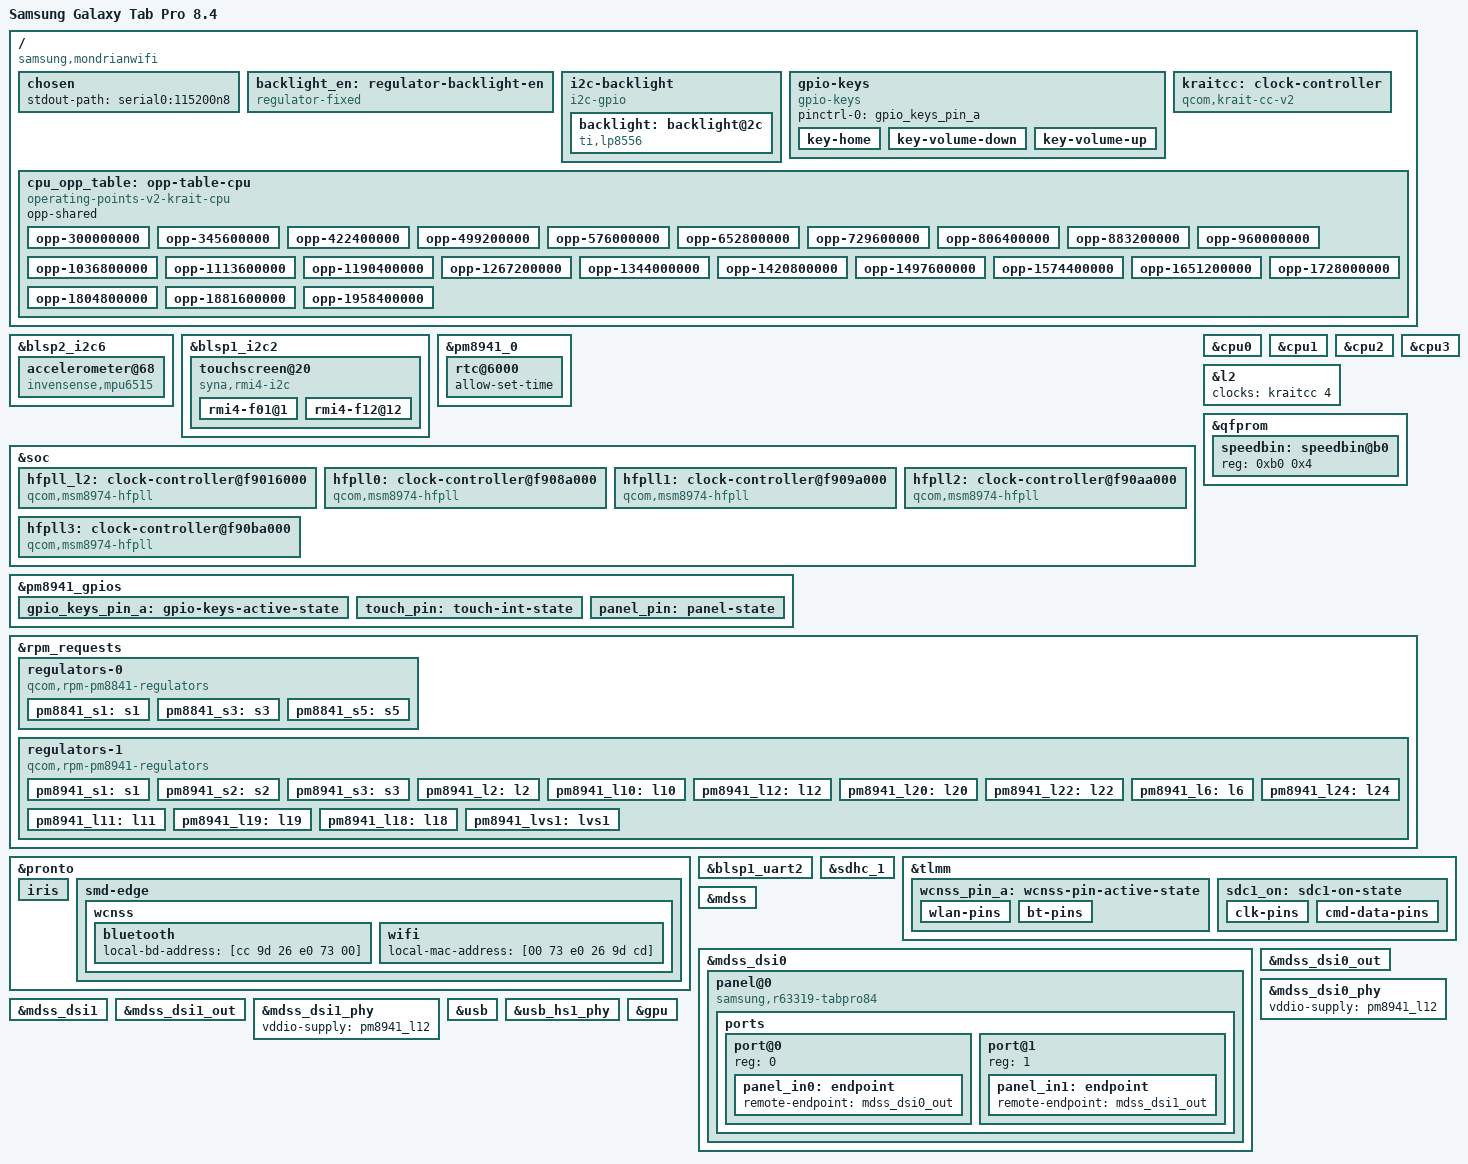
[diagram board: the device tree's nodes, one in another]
// SPDX-License-Identifier: BSD-3-Clause
/*
 * Samsung Galaxy Tab Pro 8.4 Wi-Fi (SM-T320, "mondrianwifi")
 * APQ8074 / msm8974 + PM8941 + PM8841
 *
 * DRAFT. Values traced from the downstream include chain
 * (apq8074-sec-mondrianwifi-r12.dts -> msm8974-mdss-sec.dtsi,
 *  msm8974-sec-mondrian-r12.dtsi, msm8974-sec-tabpro-common.dtsi)
 * and cross-checked against live sysfs on the running device.
 */

/dts-v1/;

#include "qcom-msm8974.dtsi"
#include "pm8841.dtsi"
#include "pm8941.dtsi"
#include <dt-bindings/input/input.h>
#include <dt-bindings/interrupt-controller/irq.h>
#include <dt-bindings/pinctrl/qcom,pmic-gpio.h>

/ {
	model = "Samsung Galaxy Tab Pro 8.4";
	compatible = "samsung,mondrianwifi", "qcom,apq8074";
	chassis-type = "tablet";

	chosen {
		stdout-path = "serial0:115200n8";
	};

	/*
	 * LP8556 backlight enable. Downstream:
	 *   lp8556,en-gpio = <&pm8941_gpios 19 0x00>
	 * The mainline lp855x binding takes a regulator, not a GPIO, so wrap it.
	 */
	backlight_en: regulator-backlight-en {
		compatible = "regulator-fixed";
		regulator-name = "backlight_en";
		gpio = <&pm8941_gpios 19 GPIO_ACTIVE_HIGH>;
		enable-active-high;
		regulator-boot-on;
	};

	/*
	 * The LP8556 sits on a BIT-BANGED i2c bus, not a hardware QUP, which is
	 * why nothing ever probed it. Downstream:
	 *   lp8556,scl-gpio = <&msmgpio 11>   lp8556,sda-gpio = <&msmgpio 10>
	 * (msmgpio == tlmm in mainline). Without this the panel scans correctly
	 * and the screen is simply unlit - indistinguishable from a dead panel.
	 */
	i2c-backlight {
		compatible = "i2c-gpio";
		sda-gpios = <&tlmm 10 (GPIO_ACTIVE_HIGH | GPIO_OPEN_DRAIN)>;
		scl-gpios = <&tlmm 11 (GPIO_ACTIVE_HIGH | GPIO_OPEN_DRAIN)>;
		i2c-gpio,delay-us = <4>;

		#address-cells = <1>;
		#size-cells = <0>;

		backlight: backlight@2c {
			compatible = "ti,lp8556";
			reg = <0x2c>;

			bl-name = "lcd-bl";
			dev-ctrl = /bits/ 8 <0x85>;
			init-brt = /bits/ 8 <0x80>;

			enable-supply = <&backlight_en>;
		};
	};

	gpio-keys {
		compatible = "gpio-keys";

		pinctrl-0 = <&gpio_keys_pin_a>;
		pinctrl-names = "default";

		key-home {
			label = "Home";
			gpios = <&pm8941_gpios 3 GPIO_ACTIVE_LOW>;
			linux,code = <KEY_HOMEPAGE>;
			debounce-interval = <15>;
		};

		key-volume-down {
			label = "Volume Down";
			gpios = <&pm8941_gpios 2 GPIO_ACTIVE_LOW>;
			linux,code = <KEY_VOLUMEDOWN>;
			debounce-interval = <15>;
		};

		key-volume-up {
			label = "Volume Up";
			gpios = <&pm8941_gpios 5 GPIO_ACTIVE_LOW>;
			linux,code = <KEY_VOLUMEUP>;
			debounce-interval = <15>;
		};
	};
};

/*
 * Touchscreen. Downstream: synaptics@20 on i2c@f9924000 (== blsp1_i2c2),
 * irq pm8941_gpios 30, avdd = l22 (3.3V live), vcc_i2c = l10 (1.85V live).
 * Wiring is identical to qcom-msm8974-samsung-hlte.dts.
 */
/*
 * Accelerometer/gyro: InvenSense MPU-6515 on BLSP2 QUP6 (vendor DT
 * msm8974-sec-mondrian-r12.dtsi: i2c@f9968000, mpu9250@68, irq gpio 86).
 * Drives screen rotation through iio-sensor-proxy.
 */
&blsp2_i2c6 {
	status = "okay";

	accelerometer@68 {
		compatible = "invensense,mpu6515";
		reg = <0x68>;
		interrupts-extended = <&tlmm 86 IRQ_TYPE_EDGE_RISING>;
		vdd-supply = <&pm8941_l18>;
		vddio-supply = <&pm8941_lvs1>;
	};
};

&blsp1_i2c2 {
	status = "okay";

	touchscreen@20 {
		compatible = "syna,rmi4-i2c";
		reg = <0x20>;

		interrupt-parent = <&pm8941_gpios>;
		interrupts = <30 IRQ_TYPE_EDGE_FALLING>;

		vdd-supply = <&pm8941_l22>;
		vio-supply = <&pm8941_l10>;

		pinctrl-0 = <&touch_pin>;
		pinctrl-names = "default";

		syna,startup-delay-ms = <100>;

		#address-cells = <1>;
		#size-cells = <0>;

		rmi4-f01@1 {
			reg = <0x1>;
			syna,nosleep-mode = <1>;
		};

		rmi4-f12@12 {
			reg = <0x12>;
			syna,sensor-type = <1>;
		};
	};
};

/* PM8941 RTC: the driver is read-only unless told otherwise; let hwclock -w
 * persist the clock, since this device has no other time source offline. */
&pm8941_0 {
	rtc@6000 {
		allow-set-time;
	};
};

/*
 * Krait CPU clocking. The bootloader parks the cores on the 300 MHz
 * secondary source and nothing in mainline ever moves them on msm8974
 * (measured: ~8x slower than rated). Wiring per the vendor kernel
 * (clock-krait-8974.c / msm8974.dtsi): five HFPLLs, the Krait clock
 * controller (v2), the speed/PVS fuse at qfprom 0xb0, and the APC supply
 * PM8841 S5 (S6..S8 are its phases). No OPP table yet: this revision only
 * registers the clocks and rails so their boot state can be read.
 */
&soc {
	hfpll_l2: clock-controller@f9016000 {
		compatible = "qcom,msm8974-hfpll", "qcom,hfpll";
		reg = <0xf9016000 0x30>, <0xf9006000 0x30>;
		#clock-cells = <0>;
		clock-output-names = "hfpll_l2";
		clocks = <&xo_board>;
		clock-names = "xo";
	};

	hfpll0: clock-controller@f908a000 {
		compatible = "qcom,msm8974-hfpll", "qcom,hfpll";
		reg = <0xf908a000 0x30>, <0xf900a000 0x30>;
		#clock-cells = <0>;
		clock-output-names = "hfpll0";
		clocks = <&xo_board>;
		clock-names = "xo";
	};

	hfpll1: clock-controller@f909a000 {
		compatible = "qcom,msm8974-hfpll", "qcom,hfpll";
		reg = <0xf909a000 0x30>, <0xf901a000 0x30>;
		#clock-cells = <0>;
		clock-output-names = "hfpll1";
		clocks = <&xo_board>;
		clock-names = "xo";
	};

	hfpll2: clock-controller@f90aa000 {
		compatible = "qcom,msm8974-hfpll", "qcom,hfpll";
		reg = <0xf90aa000 0x30>, <0xf902a000 0x30>;
		#clock-cells = <0>;
		clock-output-names = "hfpll2";
		clocks = <&xo_board>;
		clock-names = "xo";
	};

	hfpll3: clock-controller@f90ba000 {
		compatible = "qcom,msm8974-hfpll", "qcom,hfpll";
		reg = <0xf90ba000 0x30>, <0xf903a000 0x30>;
		#clock-cells = <0>;
		clock-output-names = "hfpll3";
		clocks = <&xo_board>;
		clock-names = "xo";
	};

};

/* not a memory-mapped block: the Krait muxes are reached through cp15 */
/ {
	kraitcc: clock-controller {
		compatible = "qcom,krait-cc-v2";
		clocks = <&hfpll0>, <&hfpll1>, <&hfpll2>, <&hfpll3>, <&hfpll_l2>;
		clock-names = "hfpll0", "hfpll1", "hfpll2", "hfpll3", "hfpll_l2";
		#clock-cells = <1>;
	};
};

/*
 * CPU OPPs: the vendor kernel's "qcom,speed0-pvs0-bin-v0" plan, its safe
 * fallback for this unit's speed bin 1 (no speed1 table exists downstream);
 * these voltages are what Android ran this silicon at. The ceiling is
 * raised from userspace (scaling_max_freq, /etc/local.d/cpufreq-cap.start)
 * while the RPM-voted supply is proven; see NOTES.
 */
/ {
	cpu_opp_table: opp-table-cpu {
		compatible = "operating-points-v2-krait-cpu";
		opp-shared;

		opp-300000000 {
			opp-hz = /bits/ 64 <300000000>;
			opp-microvolt = <815000 815000 1100000>;
			clock-latency-ns = <100000>;
		};

		opp-345600000 {
			opp-hz = /bits/ 64 <345600000>;
			opp-microvolt = <825000 825000 1100000>;
			clock-latency-ns = <100000>;
		};

		opp-422400000 {
			opp-hz = /bits/ 64 <422400000>;
			opp-microvolt = <835000 835000 1100000>;
			clock-latency-ns = <100000>;
		};

		opp-499200000 {
			opp-hz = /bits/ 64 <499200000>;
			opp-microvolt = <845000 845000 1100000>;
			clock-latency-ns = <100000>;
		};

		opp-576000000 {
			opp-hz = /bits/ 64 <576000000>;
			opp-microvolt = <855000 855000 1100000>;
			clock-latency-ns = <100000>;
		};

		opp-652800000 {
			opp-hz = /bits/ 64 <652800000>;
			opp-microvolt = <865000 865000 1100000>;
			clock-latency-ns = <100000>;
		};

		opp-729600000 {
			opp-hz = /bits/ 64 <729600000>;
			opp-microvolt = <875000 875000 1100000>;
			clock-latency-ns = <100000>;
		};

		opp-806400000 {
			opp-hz = /bits/ 64 <806400000>;
			opp-microvolt = <890000 890000 1100000>;
			clock-latency-ns = <100000>;
		};

		opp-883200000 {
			opp-hz = /bits/ 64 <883200000>;
			opp-microvolt = <900000 900000 1100000>;
			clock-latency-ns = <100000>;
		};

		opp-960000000 {
			opp-hz = /bits/ 64 <960000000>;
			opp-microvolt = <915000 915000 1100000>;
			clock-latency-ns = <100000>;
		};

		opp-1036800000 {
			opp-hz = /bits/ 64 <1036800000>;
			opp-microvolt = <925000 925000 1100000>;
			clock-latency-ns = <100000>;
		};

		opp-1113600000 {
			opp-hz = /bits/ 64 <1113600000>;
			opp-microvolt = <940000 940000 1100000>;
			clock-latency-ns = <100000>;
		};

		opp-1190400000 {
			opp-hz = /bits/ 64 <1190400000>;
			opp-microvolt = <950000 950000 1100000>;
			clock-latency-ns = <100000>;
		};

		opp-1267200000 {
			opp-hz = /bits/ 64 <1267200000>;
			opp-microvolt = <965000 965000 1100000>;
			clock-latency-ns = <100000>;
		};

		opp-1344000000 {
			opp-hz = /bits/ 64 <1344000000>;
			opp-microvolt = <980000 980000 1100000>;
			clock-latency-ns = <100000>;
		};

		opp-1420800000 {
			opp-hz = /bits/ 64 <1420800000>;
			opp-microvolt = <995000 995000 1100000>;
			clock-latency-ns = <100000>;
		};

		opp-1497600000 {
			opp-hz = /bits/ 64 <1497600000>;
			opp-microvolt = <1010000 1010000 1100000>;
			clock-latency-ns = <100000>;
		};

		opp-1574400000 {
			opp-hz = /bits/ 64 <1574400000>;
			opp-microvolt = <1025000 1025000 1100000>;
			clock-latency-ns = <100000>;
		};

		opp-1651200000 {
			opp-hz = /bits/ 64 <1651200000>;
			opp-microvolt = <1040000 1040000 1100000>;
			clock-latency-ns = <100000>;
		};

		opp-1728000000 {
			opp-hz = /bits/ 64 <1728000000>;
			opp-microvolt = <1055000 1055000 1100000>;
			clock-latency-ns = <100000>;
		};

		opp-1804800000 {
			opp-hz = /bits/ 64 <1804800000>;
			opp-microvolt = <1070000 1070000 1100000>;
			clock-latency-ns = <100000>;
		};

		opp-1881600000 {
			opp-hz = /bits/ 64 <1881600000>;
			opp-microvolt = <1085000 1085000 1100000>;
			clock-latency-ns = <100000>;
		};

		opp-1958400000 {
			opp-hz = /bits/ 64 <1958400000>;
			opp-microvolt = <1100000 1100000 1100000>;
			clock-latency-ns = <100000>;
		};
	};
};

&cpu0 {
	clocks = <&kraitcc 0>;
	clock-names = "cpu";
	operating-points-v2 = <&cpu_opp_table>;
	cpu-supply = <&pm8841_s5>;
	nvmem-cells = <&speedbin>;
	nvmem-cell-names = "speed_bin";
};

&cpu1 {
	clocks = <&kraitcc 1>;
	clock-names = "cpu";
	operating-points-v2 = <&cpu_opp_table>;
	cpu-supply = <&pm8841_s5>;
	nvmem-cells = <&speedbin>;
	nvmem-cell-names = "speed_bin";
};

&cpu2 {
	clocks = <&kraitcc 2>;
	clock-names = "cpu";
	operating-points-v2 = <&cpu_opp_table>;
	cpu-supply = <&pm8841_s5>;
	nvmem-cells = <&speedbin>;
	nvmem-cell-names = "speed_bin";
};

&cpu3 {
	clocks = <&kraitcc 3>;
	clock-names = "cpu";
	operating-points-v2 = <&cpu_opp_table>;
	cpu-supply = <&pm8841_s5>;
	nvmem-cells = <&speedbin>;
	nvmem-cell-names = "speed_bin";
};

&l2 {
	clocks = <&kraitcc 4>;
	clock-names = "l2";
};

&qfprom {
	/* PTE efuse: speed bin, PVS bin, PVS version (this unit: 1 / 2 / 0) */
	speedbin: speedbin@b0 {
		reg = <0xb0 0x4>;
	};
};

&pm8941_gpios {
	gpio_keys_pin_a: gpio-keys-active-state {
		pins = "gpio2", "gpio3", "gpio5";
		function = "normal";
		bias-pull-up;
		power-source = <PM8941_GPIO_S3>;
	};

	touch_pin: touch-int-state {
		pins = "gpio30";
		function = "normal";
		bias-disable;
		input-enable;
		power-source = <PM8941_GPIO_S3>;
	};

	panel_pin: panel-state {
		pins = "gpio9", "gpio14";
		function = "normal";
		bias-disable;
		power-source = <PM8941_GPIO_S3>;
		output-high;
	};
};

/*
 * Rails. Voltages below were read from live sysfs on the running device
 * (see tabpro84-port/findings/NOTES.md), not guessed:
 *   l2 = 1.200V  l10 = 1.850V  l12 = 1.800V  l22 = 3.300V
 */
&rpm_requests {
	regulators-0 {
		compatible = "qcom,rpm-pm8841-regulators";

		pm8841_s1: s1 {
			regulator-min-microvolt = <675000>;
			regulator-max-microvolt = <1050000>;
		};

		pm8841_s3: s3 {
			regulator-min-microvolt = <1050000>;
			regulator-max-microvolt = <1050000>;
		};

		/*
		 * APC (Krait) supply: 4-phase FTS S5 (+S6..S8 as phases). The
		 * SPMI arbiter denies the AP direct access to PM8841's SMPS
		 * peripherals (they read as zero), so it is voted via the RPM.
		 * Range = the vendor speed0-pvs0 plan (815 mV @ 300 MHz .. 1.1 V
		 * @ 1958 MHz); cores run in BHS mode, straight off this rail.
		 */
		pm8841_s5: s5 {
			regulator-name = "vdd_apc";
			regulator-min-microvolt = <815000>;
			regulator-max-microvolt = <1100000>;
		};
	};

	regulators-1 {
		compatible = "qcom,rpm-pm8941-regulators";

		pm8941_s1: s1 {
			regulator-min-microvolt = <1300000>;
			regulator-max-microvolt = <1300000>;
			regulator-always-on;
		};

		pm8941_s2: s2 {
			regulator-min-microvolt = <2150000>;
			regulator-max-microvolt = <2150000>;
		};

		pm8941_s3: s3 {
			regulator-min-microvolt = <1800000>;
			regulator-max-microvolt = <1800000>;
			regulator-always-on;
		};

		pm8941_l2: l2 {
			regulator-min-microvolt = <1200000>;
			regulator-max-microvolt = <1200000>;
		};

		pm8941_l10: l10 {
			regulator-min-microvolt = <1850000>;
			regulator-max-microvolt = <1850000>;
		};

		pm8941_l12: l12 {
			regulator-min-microvolt = <1800000>;
			regulator-max-microvolt = <1800000>;
			regulator-always-on;
		};

		pm8941_l20: l20 {
			regulator-min-microvolt = <2950000>;
			regulator-max-microvolt = <2950000>;
			regulator-system-load = <200000>;
			regulator-allow-set-load;
			regulator-boot-on;
		};

		pm8941_l22: l22 {
			regulator-min-microvolt = <3300000>;
			regulator-max-microvolt = <3300000>;
			regulator-boot-on;
		};

		pm8941_l6: l6 {
			regulator-min-microvolt = <1800000>;
			regulator-max-microvolt = <1800000>;
			regulator-boot-on;
		};

		pm8941_l24: l24 {
			regulator-min-microvolt = <3075000>;
			regulator-max-microvolt = <3075000>;
			regulator-boot-on;
		};

		/* WCNSS (Wi-Fi + Bluetooth) RF supplies, per every other PM8941 board */
		pm8941_l11: l11 {
			regulator-min-microvolt = <1300000>;
			regulator-max-microvolt = <1300000>;
		};

		pm8941_l19: l19 {
			regulator-min-microvolt = <2900000>;
			regulator-max-microvolt = <3350000>;
		};

		/* sensors (vendor: mpu9250-vcc / -lvs1 supplies) */
		pm8941_l18: l18 {
			regulator-min-microvolt = <2850000>;
			regulator-max-microvolt = <2850000>;
		};

		pm8941_lvs1: lvs1 {
		};
	};
};

/*
 * WCNSS: Wi-Fi and Bluetooth live on the wcn3680 behind the pronto remoteproc.
 * The signed firmware is the device's own, from the apnhlos partition
 * (image/wcnss.mdt + .b0x), installed under /lib/firmware/qcom/msm8974/mondrianwifi.
 */
&pronto {
	vddmx-supply = <&pm8841_s1>;
	vddpx-supply = <&pm8941_s3>;

	pinctrl-names = "default";
	pinctrl-0 = <&wcnss_pin_a>;

	firmware-name = "qcom/msm8974/mondrianwifi/wcnss.mdt";

	status = "okay";

	iris {
		vddxo-supply = <&pm8941_l6>;
		vddrfa-supply = <&pm8941_l11>;
		vddpa-supply = <&pm8941_l19>;
		vdddig-supply = <&pm8941_s3>;
	};

	smd-edge {
		qcom,remote-pid = <4>;
		label = "pronto";

		wcnss {
			status = "okay";

			/* addresses from the efs partition: bluetooth/bt_addr, wifi/.mac.info */
			bluetooth {
				local-bd-address = [cc 9d 26 e0 73 00];
			};

			wifi {
				local-mac-address = [00 73 e0 26 9d cd];
			};
		};
	};
};

&blsp1_uart2 {
	status = "okay";
};

&sdhc_1 {
	status = "okay";

	vmmc-supply = <&pm8941_l20>;
	vqmmc-supply = <&pm8941_s3>;

	pinctrl-0 = <&sdc1_on>;
	pinctrl-names = "default";
};

&tlmm {
	wcnss_pin_a: wcnss-pin-active-state {
		wlan-pins {
			pins = "gpio36", "gpio37", "gpio38", "gpio39", "gpio40";
			function = "wlan";
			drive-strength = <6>;
			bias-pull-down;
		};

		bt-pins {
			pins = "gpio35", "gpio43", "gpio44";
			function = "bt";
			drive-strength = <2>;
			bias-pull-down;
		};
	};

	sdc1_on: sdc1-on-state {
		clk-pins {
			pins = "sdc1_clk";
			drive-strength = <16>;
			bias-disable;
		};

		cmd-data-pins {
			pins = "sdc1_cmd", "sdc1_data";
			drive-strength = <10>;
			bias-pull-up;
		};
	};
};


&mdss {
	status = "okay";
};

&mdss_dsi0 {
	status = "okay";

	/*
	 * The panel is one physical device driven over two DSI links, each
	 * carrying one 800x2560 half. Without these the DSI manager leaves
	 * is_bonded_dsi false, each host tries to clock the FULL 1600x2560
	 * mode (~320 MHz pixel / ~1.92 GHz per lane), and the PLL rejects it:
	 *   msm_dsi_host_power_on: failed to enable link clocks. ret=-22
	 */
	qcom,dual-dsi-mode;
	qcom,master-dsi;

	vdd-supply   = <&pm8941_l22>;
	vddio-supply = <&pm8941_l12>;
	vdda-supply  = <&pm8941_l2>;

	panel@0 {
		compatible = "samsung,r63319-tabpro84";
		reg = <0>;

		/* one physical panel, one reset and one enable shared by both links */
		reset-gpios  = <&pm8941_gpios  9 GPIO_ACTIVE_LOW>;
		enable-gpios = <&pm8941_gpios 14 GPIO_ACTIVE_HIGH>;

		vdd-supply   = <&pm8941_l22>;
		vddio-supply = <&pm8941_l12>;

		backlight = <&backlight>;

		pinctrl-0 = <&panel_pin>;
		pinctrl-names = "default";

		ports {
			#address-cells = <1>;
			#size-cells = <0>;

			port@0 {
				reg = <0>;
				panel_in0: endpoint {
					remote-endpoint = <&mdss_dsi0_out>;
				};
			};

			port@1 {
				reg = <1>;
				panel_in1: endpoint {
					remote-endpoint = <&mdss_dsi1_out>;
				};
			};
		};
	};
};

&mdss_dsi0_out {
	remote-endpoint = <&panel_in0>;
	data-lanes = <0 1 2 3>;
};

&mdss_dsi0_phy {
	status = "okay";
	vddio-supply = <&pm8941_l12>;
};

&mdss_dsi1 {
	status = "okay";

	qcom,dual-dsi-mode;

	/* DSI1 is the slave link, so it runs off DSI0's PLL */
	assigned-clock-parents = <&mdss_dsi0_phy DSI_BYTE_PLL_CLK>,
				 <&mdss_dsi0_phy DSI_PIXEL_PLL_CLK>;

	vdd-supply   = <&pm8941_l22>;
	vddio-supply = <&pm8941_l12>;
	vdda-supply  = <&pm8941_l2>;
};

&mdss_dsi1_out {
	remote-endpoint = <&panel_in1>;
	data-lanes = <0 1 2 3>;
};

&mdss_dsi1_phy {
	status = "okay";
	vddio-supply = <&pm8941_l12>;
};

/*
 * USB. On a device with no exposed UART and no working display yet, USB
 * networking from the initramfs is the ONLY way to tell whether the kernel
 * booted at all. Copied from qcom-msm8974-samsung-lt03lte.dts, which is the
 * same SoC and vendor and is a working pmOS port.
 */
&usb {
	phys = <&usb_hs1_phy>;
	phy-select = <&tcsr 0xb000 0>;

	hnp-disable;
	srp-disable;
	adp-disable;

	status = "okay";
};

&usb_hs1_phy {
	v1p8-supply = <&pm8941_l6>;
	v3p3-supply = <&pm8941_l24>;

	qcom,init-seq = /bits/ 8 <0x1 0x64>;

	status = "okay";
};

/*
 * Adreno 330. The SoC dtsi ships gpu@fdb00000 as status = "disabled"; every
 * board that wants acceleration enables it itself (compare
 * qcom-msm8974pro-samsung-klte-common.dtsi). Without this, msm probes the
 * display only and prints "no GPU device was found", and freedreno fails
 * every MSM_GET_PARAM with -ENXIO, so no EGL/GLES context can be created.
 */
&gpu {
	status = "okay";
};
